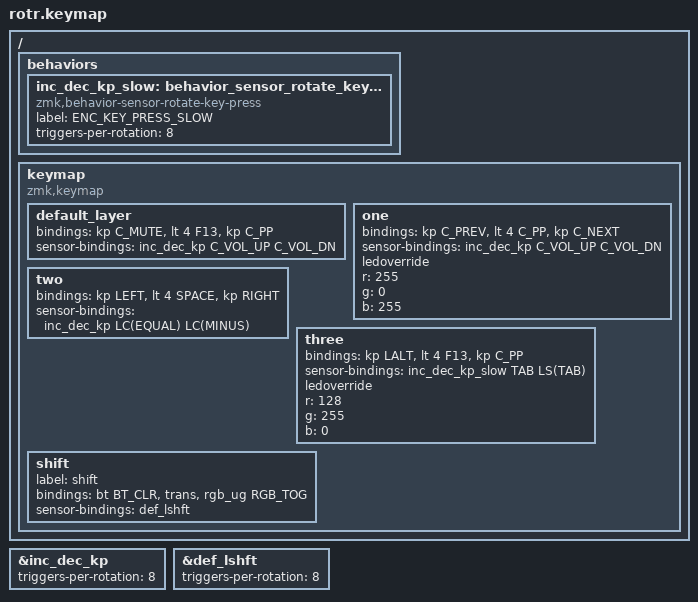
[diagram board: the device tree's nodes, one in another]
#include <behaviors.dtsi>
#include <dt-bindings/zmk/keys.h>
#include <dt-bindings/zmk/rgb.h>
#include <dt-bindings/zmk/bt.h>

&inc_dec_kp {
    triggers-per-rotation = <8>;
};
&def_lshft {
    triggers-per-rotation = <8>;
};

/ {
    behaviors {
        // Slow encoder for app switching - 2 triggers per rotation
        inc_dec_kp_slow: behavior_sensor_rotate_key_press_slow {
            compatible = "zmk,behavior-sensor-rotate-key-press";
            label = "ENC_KEY_PRESS_SLOW";
            triggers-per-rotation = <8>;
            #sensor-binding-cells = <2>;
        };
    };

    keymap {
        compatible = "zmk,keymap";

        default_layer {
            // DEFAULT COLOR: Red (layer 0 default, no ledoverride)
            // Buttons: MUTE | LAYER-TAP(shift)/F13 | PLAY/PAUSE
            // Knob:    Volume Up / Volume Down
            bindings = <&kp C_MUTE &lt 4 F13 &kp C_PP>;
            sensor-bindings = <&inc_dec_kp C_VOL_UP C_VOL_DN>;
        };
        one {
            // COLOR: Magenta (ledoverride: R:255 G:0 B:255)
            // Buttons: PREV TRACK | LAYER-TAP(shift)/PLAY-PAUSE | NEXT TRACK
            // Knob:    Volume Up / Volume Down
            bindings = <&kp C_PREV &lt 4 C_PP &kp C_NEXT>;
            sensor-bindings = <&inc_dec_kp C_VOL_UP C_VOL_DN>;
            ledoverride;
            r = <255>;
            g = <0>;
            b = <255>;
        };
        two {
            // DEFAULT COLOR: Blue (layer 2 default, no ledoverride)
            // Buttons: LEFT ARROW | LAYER-TAP(shift)/SPACE | RIGHT ARROW
            // Knob:    Zoom In (Ctrl+=) / Zoom Out (Ctrl+-)
            bindings = <&kp LEFT &lt 4 SPACE &kp RIGHT>;
            sensor-bindings = <&inc_dec_kp LC(EQUAL) LC(MINUS)>;
        };
        three {
            // DEFAULT COLOR: Yellow (layer 3 default, no ledoverride)
            // Buttons: HOLD ALT (for app switching) | LAYER-TAP(shift)/F13 | PLAY/PAUSE
            // Knob:    Tab / Shift+Tab  (Alt held by left button = Alt+Tab / Alt+Shift+Tab)
            // Usage:   Hold left button to keep Alt held, spin to select window, release to confirm
            bindings = <&kp LALT &lt 4 F13 &kp C_PP>;
            sensor-bindings = <&inc_dec_kp_slow TAB LS(TAB)>;
            ledoverride;
            r = <128>;
            g = <255>;
            b = <0>;
        };
        shift {
            // DEFAULT COLOR: Cyan/Teal (layer 4 default, no ledoverride)
            // This is the HOLD layer - active while middle button is held
            // Buttons: BT CLEAR | (pass-through) | RGB TOGGLE
            // Knob:    Change Layer
            label = "shift";
            bindings = <&bt BT_CLR &trans &rgb_ug RGB_TOG>;
            sensor-bindings = <&def_lshft>;
        };
    };
};
